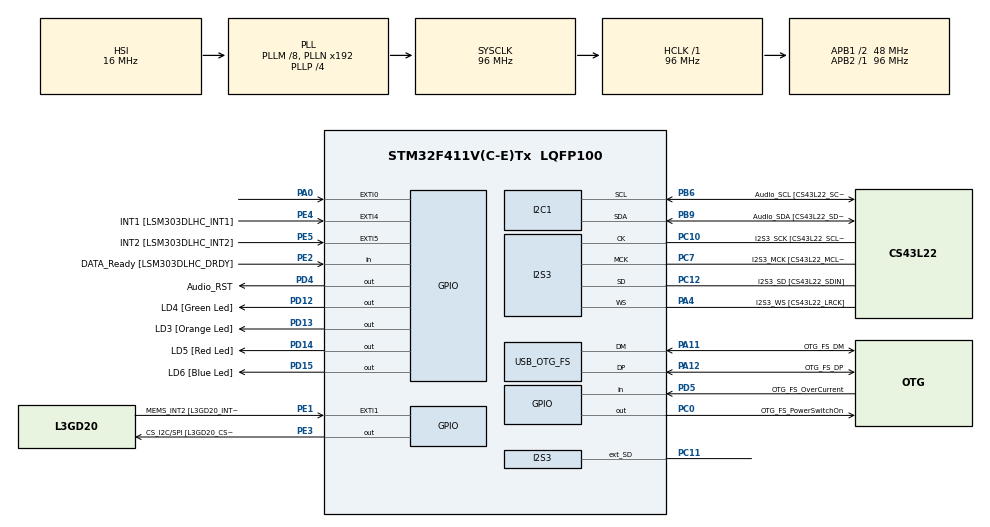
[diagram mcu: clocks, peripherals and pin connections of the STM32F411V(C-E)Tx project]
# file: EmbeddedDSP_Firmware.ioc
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Dma.I2S3_EXT_RX.1.Direction=DMA_PERIPH_TO_MEMORY
Dma.I2S3_EXT_RX.1.FIFOMode=DMA_FIFOMODE_DISABLE
Dma.I2S3_EXT_RX.1.Instance=DMA1_Stream0
Dma.I2S3_EXT_RX.1.MemDataAlignment=DMA_MDATAALIGN_HALFWORD
Dma.I2S3_EXT_RX.1.MemInc=DMA_MINC_ENABLE
Dma.I2S3_EXT_RX.1.Mode=DMA_CIRCULAR
Dma.I2S3_EXT_RX.1.PeriphDataAlignment=DMA_PDATAALIGN_HALFWORD
Dma.I2S3_EXT_RX.1.PeriphInc=DMA_PINC_DISABLE
Dma.I2S3_EXT_RX.1.Priority=DMA_PRIORITY_LOW
Dma.Request0=SPI3_TX
Dma.Request1=I2S3_EXT_RX
Dma.SPI3_TX.0.Direction=DMA_MEMORY_TO_PERIPH
Dma.SPI3_TX.0.FIFOMode=DMA_FIFOMODE_DISABLE
Dma.SPI3_TX.0.Instance=DMA1_Stream5
Dma.SPI3_TX.0.MemDataAlignment=DMA_MDATAALIGN_HALFWORD
Dma.SPI3_TX.0.MemInc=DMA_MINC_ENABLE
Dma.SPI3_TX.0.Mode=DMA_CIRCULAR
Dma.SPI3_TX.0.PeriphDataAlignment=DMA_PDATAALIGN_HALFWORD
Dma.SPI3_TX.0.PeriphInc=DMA_PINC_DISABLE
Dma.SPI3_TX.0.Priority=DMA_PRIORITY_LOW
I2S3.AudioFreq=I2S_AUDIOFREQ_48K
I2S3.ErrorAudioFreq=-2.34 %
I2S3.FullDuplexMode=I2S_FULLDUPLEXMODE_ENABLE
I2S3.Instance=SPI$Index
I2S3.RealAudioFreq=46.875 KHz
I2S3.Standard=I2S_STANDARD_PHILIPS
I2S3.VirtualMode=I2S_MODE_MASTER
Mcu.Family=STM32F4
Mcu.Name=STM32F411V(C-E)Tx
Mcu.Package=LQFP100
NVIC.DMA1_Stream0_IRQn=true\:0\:0\:false\:false\:true\:false\:true\:true
NVIC.DMA1_Stream5_IRQn=true\:0\:0\:false\:false\:true\:false\:true\:true
NVIC.OTG_FS_IRQn=true\:0\:0\:false\:false\:true\:true\:true\:true
NVIC.PriorityGroup=NVIC_PRIORITYGROUP_0
PA0-WKUP.GPIO_ModeDefaultEXTI=GPIO_MODE_EVT_RISING
PA0-WKUP.Signal=GPXTI0
PA10.GPIO_Label=OTG_FS_ID
PA10.Signal=USB_OTG_FS_ID
PA11.GPIO_Label=OTG_FS_DM
PA11.Mode=Device_Only
PA11.Signal=USB_OTG_FS_DM
PA12.GPIO_Label=OTG_FS_DP
PA12.Mode=Device_Only
PA12.Signal=USB_OTG_FS_DP
PA13.GPIO_Label=SWDIO
PA13.Mode=Serial_Wire
PA13.Signal=SYS_JTMS-SWDIO
PA14.GPIO_Label=SWCLK
PA14.Mode=Serial_Wire
PA14.Signal=SYS_JTCK-SWCLK
PA4.GPIO_Label=I2S3_WS [CS43L22_LRCK]
PA4.GPIO_Mode=GPIO_MODE_AF_PP
PA4.GPIO_PuPd=GPIO_NOPULL
PA4.GPIO_Speed=GPIO_SPEED_FREQ_LOW
PA4.Mode=Full_Duplex_Master
PA4.Signal=I2S3_WS
PA5.GPIO_Label=SPI1_SCK [L3GD20_SC/SPC]
PA5.Signal=SPI1_SCK
PA6.GPIO_Label=SPI1_MISO [L3GD20_AS0/SDO]
PA6.Signal=SPI1_MISO
PA7.GPIO_Label=SPI1_MOSI [L3GD20_SDA/SDI/SDO]
PA7.Signal=SPI1_MOSI
PB10.GPIO_Label=CLK_IN [MP45DT02_CLK]
PB10.Signal=I2S2_CK
PB12.Signal=I2S2_WS
PB3.GPIO_Label=SWO
PB3.Signal=SYS_JTDO-SWO
PB6.GPIO_Label=Audio_SCL [CS43L22_SCL]
PB6.GPIO_Mode=GPIO_MODE_AF_OD
PB6.GPIO_Pu=GPIO_PULLUP
PB6.GPIO_PuPd=GPIO_NOPULL
PB6.GPIO_Speed=GPIO_SPEED_FREQ_LOW
PB6.Mode=I2C
PB6.Signal=I2C1_SCL
PB9.GPIO_Label=Audio_SDA [CS43L22_SDA]
PB9.GPIO_Mode=GPIO_MODE_AF_OD
PB9.GPIO_Pu=GPIO_PULLUP
PB9.GPIO_PuPd=GPIO_NOPULL
PB9.GPIO_Speed=GPIO_SPEED_FREQ_LOW
PB9.Mode=I2C
PB9.Signal=I2C1_SDA
PC0.GPIO_Label=OTG_FS_PowerSwitchOn
PC0.PinState=GPIO_PIN_SET
PC0.Signal=GPIO_Output
PC10.GPIO_Label=I2S3_SCK [CS43L22_SCLK]
PC10.GPIO_Mode=GPIO_MODE_AF_PP
PC10.GPIO_PuPd=GPIO_NOPULL
PC10.GPIO_Speed=GPIO_SPEED_FREQ_LOW
PC10.Mode=Full_Duplex_Master
PC10.Signal=I2S3_CK
PC11.Mode=Full_Duplex_Master
PC11.Signal=I2S3_ext_SD
PC12.GPIO_Label=I2S3_SD [CS43L22_SDIN]
PC12.GPIO_Mode=GPIO_MODE_AF_PP
PC12.GPIO_PuPd=GPIO_NOPULL
PC12.GPIO_Speed=GPIO_SPEED_FREQ_LOW
PC12.Mode=Full_Duplex_Master
PC12.Signal=I2S3_SD
PC14-OSC32_IN.GPIO_Label=PC14-OSC32_IN
PC14-OSC32_IN.Mode=LSE-External-Oscillator
PC14-OSC32_IN.Signal=RCC_OSC32_IN
PC15-OSC32_OUT.GPIO_Label=PC15-OSC32_OUT
PC15-OSC32_OUT.Mode=LSE-External-Oscillator
PC15-OSC32_OUT.Signal=RCC_OSC32_OUT
PC3.GPIO_Label=PDM_OUT [MP45DT02_DOUT]
PC3.Signal=I2S2_SD
PC7.GPIO_Label=I2S3_MCK [CS43L22_MCLK]
PC7.GPIO_Mode=GPIO_MODE_AF_PP
PC7.GPIO_PuPd=GPIO_NOPULL
PC7.GPIO_Speed=GPIO_SPEED_FREQ_LOW
PC7.Mode=Master_Clock_Activated
PC7.Signal=I2S3_MCK
PD12.GPIO_Label=LD4 [Green Led]
PD12.GPIO_PuPd=GPIO_NOPULL
PD12.GPIO_Speed=GPIO_SPEED_FREQ_LOW
PD12.Signal=GPIO_Output
PD13.GPIO_Label=LD3 [Orange Led]
PD13.GPIO_PuPd=GPIO_NOPULL
PD13.GPIO_Speed=GPIO_SPEED_FREQ_LOW
PD13.Signal=GPIO_Output
PD14.GPIO_Label=LD5 [Red Led]
PD14.GPIO_PuPd=GPIO_NOPULL
PD14.GPIO_Speed=GPIO_SPEED_FREQ_LOW
PD14.Signal=GPIO_Output
PD15.GPIO_Label=LD6 [Blue Led]
PD15.GPIO_PuPd=GPIO_NOPULL
PD15.GPIO_Speed=GPIO_SPEED_FREQ_LOW
PD15.Signal=GPIO_Output
PD4.GPIO_Label=Audio_RST
PD4.PinState=GPIO_PIN_SET
PD4.Signal=GPIO_Output
PD5.GPIO_Label=OTG_FS_OverCurrent
PD5.Signal=GPIO_Input
PE1.GPIO_Label=MEMS_INT2 [L3GD20_INT2]
PE1.GPIO_ModeDefaultEXTI=GPIO_MODE_EVT_RISING
PE1.Signal=GPXTI1
PE2.GPIO_Label=DATA_Ready [LSM303DLHC_DRDY]
PE2.Signal=GPIO_Input
PE3.GPIO_Label=CS_I2C/SPI [L3GD20_CS_I2C/SPI]
PE3.Signal=GPIO_Output
PE4.GPIO_Label=INT1 [LSM303DLHC_INT1]
PE4.GPIO_ModeDefaultEXTI=GPIO_MODE_EVT_RISING
PE4.Signal=GPXTI4
PE5.GPIO_Label=INT2 [LSM303DLHC_INT2]
PE5.GPIO_ModeDefaultEXTI=GPIO_MODE_EVT_RISING
PE5.Signal=GPXTI5
PH0\ -\ OSC_IN.GPIO_Label=PH0-OSC_IN
PH0\ -\ OSC_IN.Signal=RCC_OSC_IN
PH1\ -\ OSC_OUT.GPIO_Label=PH1-OSC_OUT
PH1\ -\ OSC_OUT.Signal=RCC_OSC_OUT
ProjectManager.HeapSize=0x200
ProjectManager.StackSize=0x400
ProjectManager.TargetToolchain=CMake
RCC.48MHZClocksFreq_Value=48000000
RCC.AHBFreq_Value=96000000
RCC.APB1CLKDivider=RCC_HCLK_DIV2
RCC.APB1Freq_Value=48000000
RCC.APB1TimFreq_Value=96000000
RCC.APB2Freq_Value=96000000
RCC.APB2TimFreq_Value=96000000
RCC.CortexFreq_Value=96000000
RCC.HCLKFreq_Value=96000000
RCC.HSE_VALUE=8000000
RCC.HSI_VALUE=16000000
RCC.PLLI2SM=8
RCC.PLLM=8
RCC.PLLP=RCC_PLLP_DIV4
RCC.PLLQ=8
RCC.PLLSource=RCC_PLLSOURCE_HSI
RCC.SYSCLKFreq_VALUE=96000000
RCC.SYSCLKSource=RCC_SYSCLKSOURCE_PLLCLK
RCC.VCOOutputFreq_Value=384000000
USB_DEVICE.CLASS_NAME_FS=CDC
USB_DEVICE.VirtualMode=Cdc
USB_DEVICE.VirtualModeFS=Cdc_FS
USB_OTG_FS.VirtualMode=Device_Only
VP_USB_DEVICE_VS_USB_DEVICE_CDC_FS.Mode=CDC_FS
board=STM32F411E-DISCO

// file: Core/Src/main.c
/* USER CODE BEGIN Header */
/**
  ******************************************************************************
  * @file           : main.c
  * @brief          : Main program body
  ******************************************************************************
  */
/* USER CODE END Header */
#include "main.h"
#include "dma.h"
#include "i2c.h"
#include "i2s.h"
#include "usb_device.h"
#include "gpio.h"

/* USER CODE BEGIN Includes */
#include "audio_dac.h"
#include "app_main.h"

void SystemClock_Config(void);
/* USER CODE END Includes */

void SystemClock_Config(void);

int main(void)
{

  /* MCU Configuration--------------------------------------------------------*/

  /* Reset of all peripherals, Initializes the Flash interface and the Systick. */
  HAL_Init();

  /* Configure the system clock */
  SystemClock_Config();

  /* Initialize all configured peripherals */
  MX_GPIO_Init();
  MX_DMA_Init();
  MX_I2C1_Init();
  MX_I2S3_Init();
  MX_USB_DEVICE_Init();
  /* USER CODE BEGIN 2 */
    if (AudioDAC_Init() != 0)
    {
        HAL_GPIO_WritePin(GPIOD, GPIO_PIN_13, GPIO_PIN_SET); // Orange LED - DAC error
        Error_Handler();
    }

    app_main();
  /* USER CODE END 2 */

  /* Infinite loop */
  while (1)
  {

  }
}

void SystemClock_Config(void)
{
  RCC_OscInitTypeDef RCC_OscInitStruct = {0};
  RCC_ClkInitTypeDef RCC_ClkInitStruct = {0};

  /** Configure the main internal regulator output voltage
  */
  __HAL_RCC_PWR_CLK_ENABLE();
  __HAL_PWR_VOLTAGESCALING_CONFIG(PWR_REGULATOR_VOLTAGE_SCALE1);

  /** Initializes the RCC Oscillators according to the specified parameters
  * in the RCC_OscInitTypeDef structure.
  */
  RCC_OscInitStruct.OscillatorType = RCC_OSCILLATORTYPE_HSI;
  RCC_OscInitStruct.HSIState = RCC_HSI_ON;
  RCC_OscInitStruct.HSICalibrationValue = RCC_HSICALIBRATION_DEFAULT;
  RCC_OscInitStruct.PLL.PLLState = RCC_PLL_ON;
  RCC_OscInitStruct.PLL.PLLSource = RCC_PLLSOURCE_HSI;
  RCC_OscInitStruct.PLL.PLLM = 8;
  RCC_OscInitStruct.PLL.PLLN = 192;
  RCC_OscInitStruct.PLL.PLLP = RCC_PLLP_DIV4;
  RCC_OscInitStruct.PLL.PLLQ = 8;
  if (HAL_RCC_OscConfig(&RCC_OscInitStruct) != HAL_OK)
  {
    Error_Handler();
  }

  /** Initializes the CPU, AHB and APB buses clocks
  */
  RCC_ClkInitStruct.ClockType = RCC_CLOCKTYPE_HCLK|RCC_CLOCKTYPE_SYSCLK
                              |RCC_CLOCKTYPE_PCLK1|RCC_CLOCKTYPE_PCLK2;
  RCC_ClkInitStruct.SYSCLKSource = RCC_SYSCLKSOURCE_PLLCLK;
  RCC_ClkInitStruct.AHBCLKDivider = RCC_SYSCLK_DIV1;
  RCC_ClkInitStruct.APB1CLKDivider = RCC_HCLK_DIV2;
  RCC_ClkInitStruct.APB2CLKDivider = RCC_HCLK_DIV1;

  if (HAL_RCC_ClockConfig(&RCC_ClkInitStruct, FLASH_LATENCY_3) != HAL_OK)
  {
    Error_Handler();
  }
}

void Error_Handler(void)
{
  __disable_irq();
  while (1)
  {
  }
}
